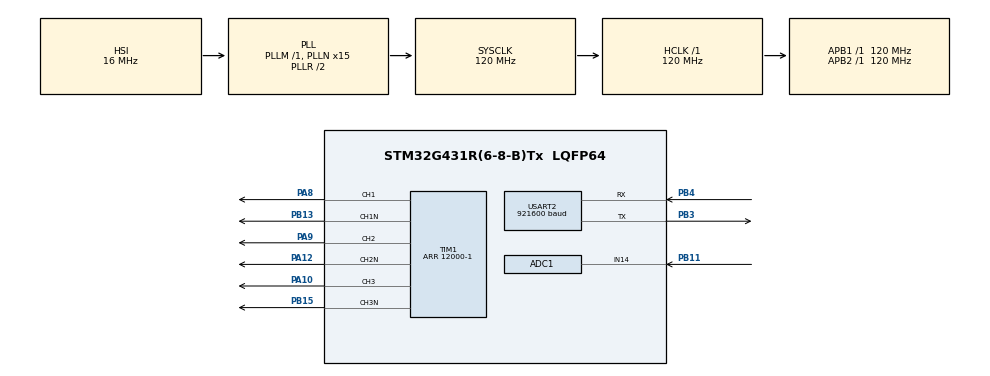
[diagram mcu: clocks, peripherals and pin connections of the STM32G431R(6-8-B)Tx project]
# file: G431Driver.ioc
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ADC1.Channel-1\#ChannelRegularConversion=ADC_CHANNEL_14
ADC1.ClockPrescaler=ADC_CLOCK_SYNC_PCLK_DIV2
ADC1.ContinuousConvMode=ENABLE
ADC1.DMAContinuousRequests=DISABLE
ADC1.EOCSelection=ADC_EOC_SINGLE_CONV
ADC1.NbrOfConversionFlag=1
ADC1.OffsetNumber-1\#ChannelRegularConversion=ADC_OFFSET_NONE
ADC1.Rank-1\#ChannelRegularConversion=1
ADC1.SamplingTime-1\#ChannelRegularConversion=ADC_SAMPLETIME_47CYCLES_5
ADC1.master=1
Mcu.Family=STM32G4
Mcu.Name=STM32G431R(6-8-B)Tx
Mcu.Package=LQFP64
NVIC.PriorityGroup=NVIC_PRIORITYGROUP_4
NVIC.TIM1_UP_TIM16_IRQn=true\:0\:0\:false\:false\:true\:true\:true\:true
PA10.Signal=S_TIM1_CH3
PA12.Mode=PWM Generation2 CH2 CH2N
PA12.Signal=TIM1_CH2N
PA13.Mode=Serial_Wire
PA13.Signal=SYS_JTMS-SWDIO
PA14.Mode=Serial_Wire
PA14.Signal=SYS_JTCK-SWCLK
PA8.Signal=S_TIM1_CH1
PA9.Signal=S_TIM1_CH2
PB11.Mode=IN14-Single-Ended
PB11.Signal=ADC1_IN14
PB13.Mode=PWM Generation1 CH1 CH1N
PB13.Signal=TIM1_CH1N
PB15.Mode=PWM Generation3 CH3 CH3N
PB15.Signal=TIM1_CH3N
PB3.Mode=Asynchronous
PB3.Signal=USART2_TX
PB4.Mode=Asynchronous
PB4.Signal=USART2_RX
PC13.Signal=TIM1_BKIN
PF0-OSC_IN.Mode=HSE-External-Oscillator
PF0-OSC_IN.Signal=RCC_OSC_IN
PF1-OSC_OUT.Mode=HSE-External-Oscillator
PF1-OSC_OUT.Signal=RCC_OSC_OUT
ProjectManager.HeapSize=0x200
ProjectManager.StackSize=0x400
ProjectManager.TargetToolchain=STM32CubeIDE
RCC.ADC12Freq_Value=120000000
RCC.AHBFreq_Value=120000000
RCC.APB1Freq_Value=120000000
RCC.APB1TimFreq_Value=120000000
RCC.APB2Freq_Value=120000000
RCC.APB2TimFreq_Value=120000000
RCC.CortexFreq_Value=120000000
RCC.EXTERNAL_CLOCK_VALUE=12288000
RCC.HCLKFreq_Value=120000000
RCC.HSE_VALUE=8000000
RCC.HSI48_VALUE=48000000
RCC.HSI_VALUE=16000000
RCC.LSE_VALUE=32768
RCC.PLLN=15
RCC.PREFETCH_ENABLE=0
RCC.SYSCLKFreq_VALUE=120000000
RCC.SYSCLKSource=RCC_SYSCLKSOURCE_PLLCLK
RCC.USBFreq_Value=120000000
RCC.VCOOutputFreq_Value=240000000
SH.S_TIM1_CH1.0=TIM1_CH1,PWM Generation1 CH1 CH1N
SH.S_TIM1_CH2.0=TIM1_CH2,PWM Generation2 CH2 CH2N
SH.S_TIM1_CH3.0=TIM1_CH3,PWM Generation3 CH3 CH3N
TIM1.AutoReloadPreload=TIM_AUTORELOAD_PRELOAD_ENABLE
TIM1.BreakFilter=2
TIM1.Channel-PWM\ Generation1\ CH1\ CH1N=TIM_CHANNEL_1
TIM1.Channel-PWM\ Generation2\ CH2\ CH2N=TIM_CHANNEL_2
TIM1.Channel-PWM\ Generation3\ CH3\ CH3N=TIM_CHANNEL_3
TIM1.CounterMode=TIM_COUNTERMODE_CENTERALIGNED1
TIM1.DeadTime=120
TIM1.PeriodNoDither=12000-1
TIM1.RepetitionCounter=1
TIM1.TIM_MasterOutputTrigger=TIM_TRGO_ENABLE
TIM1.TIM_MasterOutputTrigger2=TIM_TRGO2_ENABLE
USART2.BaudRate=921600
USART2.VirtualMode-Asynchronous=VM_ASYNC
VP_SYS_VS_DBSignals.Mode=DisableDeadBatterySignals
VP_TIM1_VS_ClockSourceINT.Mode=Internal
board=custom

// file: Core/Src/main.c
/* USER CODE BEGIN Header */
/**
  ******************************************************************************
  * @file           : main.c
  * @brief          : Main program body
  ******************************************************************************
  * @attention
  *
  * Copyright (c) 2025 STMicroelectronics.
  * All rights reserved.
  *
  * This software is licensed under terms that can be found in the LICENSE file
  * in the root directory of this software component.
  * If no LICENSE file comes with this software, it is provided AS-IS.
  *
  ******************************************************************************
  */
/* USER CODE END Header */
#include "main.h"
#include "adc.h"
#include "tim.h"
#include "usart.h"
#include "gpio.h"

/* USER CODE BEGIN Includes */
#include "stdio.h"
#include "Myfoc.h"
#include "math.h"
/* USER CODE END Includes */

/* USER CODE BEGIN PTD */
extern uint16_t Timer6_Nums;
/* USER CODE END PTD */

void SystemClock_Config(void);

int main(void)
{

  /* MCU Configuration--------------------------------------------------------*/

  /* Reset of all peripherals, Initializes the Flash interface and the Systick. */
  HAL_Init();

  /* Configure the system clock */
  SystemClock_Config();

  /* Initialize all configured peripherals */
  MX_GPIO_Init();
  MX_USART2_UART_Init();
  MX_ADC1_Init();
  MX_TIM1_Init();
  /* USER CODE BEGIN 2 */

  HAL_TIM_Base_Start_IT(&htim1);

  // 在main函数的初始化部分之后（/* USER CODE BEGIN 2 */ 之后）
  // 可以首先执行ADC校准:cite[9]:cite[10]
  if (HAL_ADCEx_Calibration_Start(&hadc1, ADC_SINGLE_ENDED) != HAL_OK)
  {
    Error_Handler();
  }

  /* USER CODE END 2 */

  /* Infinite loop */
  /* USER CODE BEGIN WHILE */
  while (1)
  {
	  // TIM6 为 10K电流环
	  if(Timer6_Nums >= 100) // 10ms
	  {
		  UART_Send();
		  Vbus_Sense(&Motor); // 母线电压读取

		  Timer6_Nums = 0;
	  }

    /* USER CODE END WHILE */

  }
}

void SystemClock_Config(void)
{
  RCC_OscInitTypeDef RCC_OscInitStruct = {0};
  RCC_ClkInitTypeDef RCC_ClkInitStruct = {0};

  /** Configure the main internal regulator output voltage
  */
  HAL_PWREx_ControlVoltageScaling(PWR_REGULATOR_VOLTAGE_SCALE1);

  /** Initializes the RCC Oscillators according to the specified parameters
  * in the RCC_OscInitTypeDef structure.
  */
  RCC_OscInitStruct.OscillatorType = RCC_OSCILLATORTYPE_HSI;
  RCC_OscInitStruct.HSIState = RCC_HSI_ON;
  RCC_OscInitStruct.HSICalibrationValue = RCC_HSICALIBRATION_DEFAULT;
  RCC_OscInitStruct.PLL.PLLState = RCC_PLL_ON;
  RCC_OscInitStruct.PLL.PLLSource = RCC_PLLSOURCE_HSI;
  RCC_OscInitStruct.PLL.PLLM = RCC_PLLM_DIV1;
  RCC_OscInitStruct.PLL.PLLN = 15;
  RCC_OscInitStruct.PLL.PLLP = RCC_PLLP_DIV2;
  RCC_OscInitStruct.PLL.PLLQ = RCC_PLLQ_DIV2;
  RCC_OscInitStruct.PLL.PLLR = RCC_PLLR_DIV2;
  if (HAL_RCC_OscConfig(&RCC_OscInitStruct) != HAL_OK)
  {
    Error_Handler();
  }

  /** Initializes the CPU, AHB and APB buses clocks
  */
  RCC_ClkInitStruct.ClockType = RCC_CLOCKTYPE_HCLK|RCC_CLOCKTYPE_SYSCLK
                              |RCC_CLOCKTYPE_PCLK1|RCC_CLOCKTYPE_PCLK2;
  RCC_ClkInitStruct.SYSCLKSource = RCC_SYSCLKSOURCE_PLLCLK;
  RCC_ClkInitStruct.AHBCLKDivider = RCC_SYSCLK_DIV1;
  RCC_ClkInitStruct.APB1CLKDivider = RCC_HCLK_DIV1;
  RCC_ClkInitStruct.APB2CLKDivider = RCC_HCLK_DIV1;

  if (HAL_RCC_ClockConfig(&RCC_ClkInitStruct, FLASH_LATENCY_3) != HAL_OK)
  {
    Error_Handler();
  }
}

void Error_Handler(void)
{
  __disable_irq();
  while (1)
  {
  }
}
